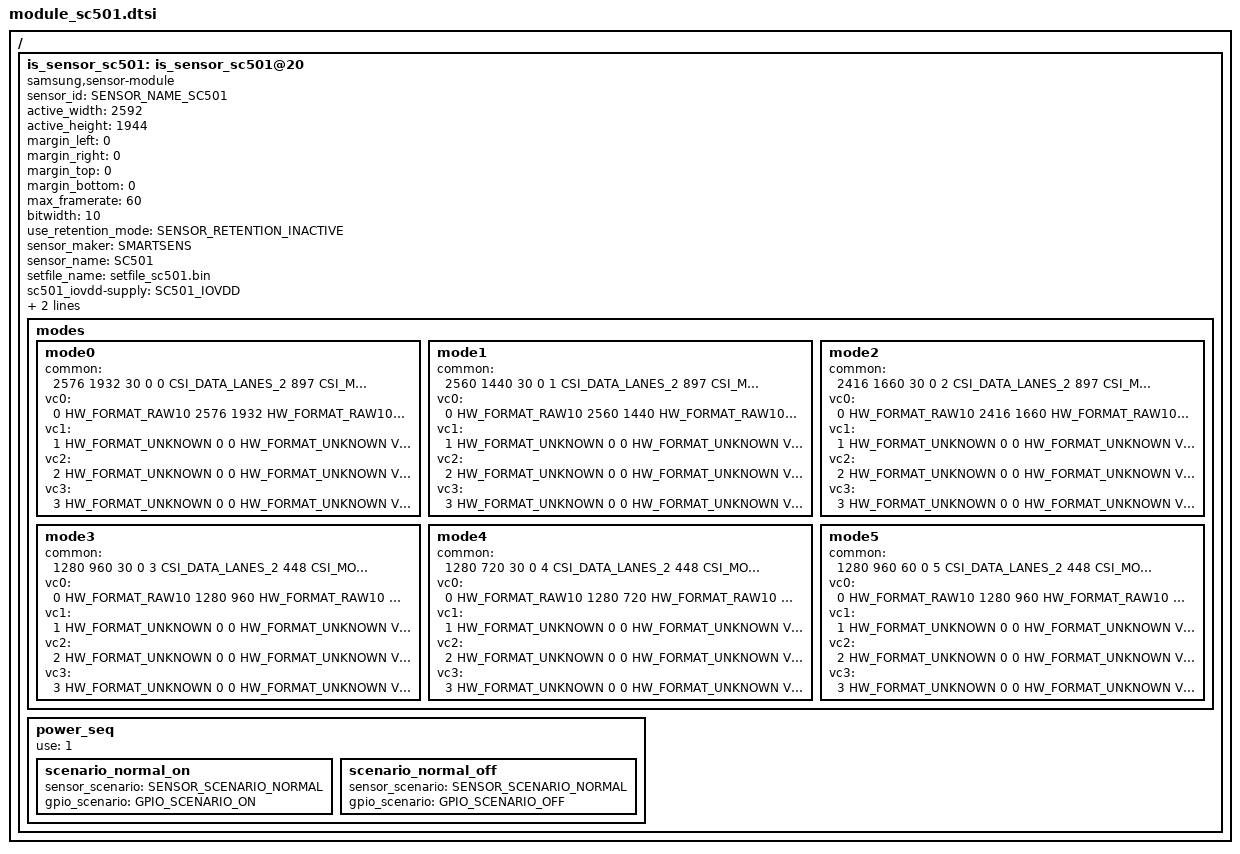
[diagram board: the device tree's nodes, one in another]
/*
 * SAMSUNG EXYNOSxxxx board camera device tree source
 *
 * Copyright (c) 2022 Samsung Electronics Co., Ltd.
 *        http://www.samsung.com
 *
 * This program is free software; you can redistribute it and/or modify
 * it under the terms of the GNU General Public License version 2 as
 * published by the Free Software Foundation.
 */

#include <dt-bindings/camera/exynos_is_dt.h>

#ifndef USE_VENDOR_PWR_PIN_NAME
#define SC501_IOVDD	<>
#define SC501_AVDD	<>
#define SC501_DVDD	<>
#endif

/ {
	fragment@camera {
		target-path = "/";
		__overlay__ {
			is_sensor_sc501: is_sensor_sc501@20 {
				compatible = "samsung,sensor-module";

				/* common */
				sensor_id = <SENSOR_NAME_SC501>;
				active_width = <2592>;
				active_height = <1944>;
				margin_left = <0>;
				margin_right = <0>;
				margin_top = <0>;
				margin_bottom = <0>;
				max_framerate = <60>;
				bitwidth = <10>;
				use_retention_mode = <SENSOR_RETENTION_INACTIVE>;
				sensor_maker = "SMARTSENS";
				sensor_name = "SC501";
				setfile_name = "setfile_sc501.bin";

				sc501_iovdd-supply = SC501_IOVDD;
				sc501_avdd-supply = SC501_AVDD;
				sc501_dvdd-supply = SC501_DVDD;

				status = "okay";

				/* sensor modes */
				modes {
						/* common = <width, height, fps, settle, mode, lane, speed, interleave, lrte, pd_mode> */
						/* vcX = <map, hwformat, width, height, hwformat, type, width, height> */

					/* 0 : 2576x1932@30fps 4:3 */
					mode0 {
						common = <2576 1932 30 0 0 CSI_DATA_LANES_2 897 CSI_MODE_VC_ONLY LRTE_DISABLE PD_NONE EX_NONE>;
						vc0 = </* in */ 0 HW_FORMAT_RAW10 2576 1932	/* out */ HW_FORMAT_RAW10 VC_NOTHING 0 0>;
						vc1 = </* in */ 1 HW_FORMAT_UNKNOWN 0 0		/* out */ HW_FORMAT_UNKNOWN VC_NOTHING 0 0>;
						vc2 = </* in */ 2 HW_FORMAT_UNKNOWN 0 0		/* out */ HW_FORMAT_UNKNOWN VC_NOTHING 0 0>;
						vc3 = </* in */ 3 HW_FORMAT_UNKNOWN 0 0		/* out */ HW_FORMAT_UNKNOWN VC_NOTHING 0 0>;
					};

					/* 1 : 2560x1440@30fps 16:9 */
					mode1 {
						common = <2560 1440 30 0 1 CSI_DATA_LANES_2 897 CSI_MODE_VC_ONLY LRTE_DISABLE PD_NONE EX_NONE>;
						vc0 = </* in */ 0 HW_FORMAT_RAW10 2560 1440	/* out */ HW_FORMAT_RAW10 VC_NOTHING 0 0>;
						vc1 = </* in */ 1 HW_FORMAT_UNKNOWN 0 0		/* out */ HW_FORMAT_UNKNOWN VC_NOTHING 0 0>;
						vc2 = </* in */ 2 HW_FORMAT_UNKNOWN 0 0		/* out */ HW_FORMAT_UNKNOWN VC_NOTHING 0 0>;
						vc3 = </* in */ 3 HW_FORMAT_UNKNOWN 0 0		/* out */ HW_FORMAT_UNKNOWN VC_NOTHING 0 0>;
					};

					/* 2 : 2416x1660@30fps */
					mode2 {
						common = <2416 1660 30 0 2 CSI_DATA_LANES_2 897 CSI_MODE_VC_ONLY LRTE_DISABLE PD_NONE EX_NONE>;
						vc0 = </* in */ 0 HW_FORMAT_RAW10 2416 1660	/* out */ HW_FORMAT_RAW10 VC_NOTHING 0 0>;
						vc1 = </* in */ 1 HW_FORMAT_UNKNOWN 0 0		/* out */ HW_FORMAT_UNKNOWN VC_NOTHING 0 0>;
						vc2 = </* in */ 2 HW_FORMAT_UNKNOWN 0 0		/* out */ HW_FORMAT_UNKNOWN VC_NOTHING 0 0>;
						vc3 = </* in */ 3 HW_FORMAT_UNKNOWN 0 0		/* out */ HW_FORMAT_UNKNOWN VC_NOTHING 0 0>;
					};

					/* 3 : 1280x960@30fps 4:3 */
					mode3 {
						common = <1280 960 30 0 3 CSI_DATA_LANES_2 448 CSI_MODE_VC_ONLY LRTE_DISABLE PD_NONE EX_NONE>;
						vc0 = </* in */ 0 HW_FORMAT_RAW10 1280 960	/* out */ HW_FORMAT_RAW10 VC_NOTHING 0 0>;
						vc1 = </* in */ 1 HW_FORMAT_UNKNOWN 0 0		/* out */ HW_FORMAT_UNKNOWN VC_NOTHING 0 0>;
						vc2 = </* in */ 2 HW_FORMAT_UNKNOWN 0 0		/* out */ HW_FORMAT_UNKNOWN VC_NOTHING 0 0>;
						vc3 = </* in */ 3 HW_FORMAT_UNKNOWN 0 0		/* out */ HW_FORMAT_UNKNOWN VC_NOTHING 0 0>;
					};

					/* 4 : 1280x720@30fps 16:9 */
					mode4 {
						common = <1280 720 30 0 4 CSI_DATA_LANES_2 448 CSI_MODE_VC_ONLY LRTE_DISABLE PD_NONE EX_NONE>;
						vc0 = </* in */ 0 HW_FORMAT_RAW10 1280 720	/* out */ HW_FORMAT_RAW10 VC_NOTHING 0 0>;
						vc1 = </* in */ 1 HW_FORMAT_UNKNOWN 0 0		/* out */ HW_FORMAT_UNKNOWN VC_NOTHING 0 0>;
						vc2 = </* in */ 2 HW_FORMAT_UNKNOWN 0 0		/* out */ HW_FORMAT_UNKNOWN VC_NOTHING 0 0>;
						vc3 = </* in */ 3 HW_FORMAT_UNKNOWN 0 0		/* out */ HW_FORMAT_UNKNOWN VC_NOTHING 0 0>;
					};

					/* 5 : 1280x960@60fps 4:3 */
					mode5 {
						common = <1280 960 60 0 5 CSI_DATA_LANES_2 448 CSI_MODE_VC_ONLY LRTE_DISABLE PD_NONE EX_NONE>;
						vc0 = </* in */ 0 HW_FORMAT_RAW10 1280 960	/* out */ HW_FORMAT_RAW10 VC_NOTHING 0 0>;
						vc1 = </* in */ 1 HW_FORMAT_UNKNOWN 0 0		/* out */ HW_FORMAT_UNKNOWN VC_NOTHING 0 0>;
						vc2 = </* in */ 2 HW_FORMAT_UNKNOWN 0 0		/* out */ HW_FORMAT_UNKNOWN VC_NOTHING 0 0>;
						vc3 = </* in */ 3 HW_FORMAT_UNKNOWN 0 0		/* out */ HW_FORMAT_UNKNOWN VC_NOTHING 0 0>;
					};

				};

				power_seq {
					use = <1>;

					scenario_normal_on {
						sensor_scenario = <SENSOR_SCENARIO_NORMAL>;
						gpio_scenario = <GPIO_SCENARIO_ON>;

						/* A start node number should be over the 10 for reserved number 0~9. */
						/* pname = "name"; pin = <act value dealy voltage>; gpio = <gpx# # 0x1>; */
					};

					scenario_normal_off {
						sensor_scenario = <SENSOR_SCENARIO_NORMAL>;
						gpio_scenario = <GPIO_SCENARIO_OFF>;

						/* A start node number should be over the 10 for reserved number 0~9. */
						/* pname = "name"; pin = <act value dealy voltage>; gpio = <gpx# # 0x1>; */
					};
#if 0
					scenario_read_rom_on {
						sensor_scenario = <SENSOR_SCENARIO_READ_ROM>;
						gpio_scenario = <GPIO_SCENARIO_ON>;
					};

					scenario_read_rom_off {
						sensor_scenario = <SENSOR_SCENARIO_READ_ROM>;
						gpio_scenario = <GPIO_SCENARIO_OFF>;
					};

					scenario_vision_on {
						sensor_scenario = <SENSOR_SCENARIO_VISION>;
						gpio_scenario = <GPIO_SCENARIO_ON>;

						/* A start node number should be over the 10 for reserved number 0~9. */
						/* pname = "name"; 		pin = <act value dealy voltage>;	gpio = <gpx# # 0x1>; */
					};

					scenario_vision_off {
						sensor_scenario = <SENSOR_SCENARIO_VISION>;
						gpio_scenario = <GPIO_SCENARIO_OFF>;

						/* A start node number should be over the 10 for reserved number 0~9. */
						/* pname = "name"; 		pin = <act value dealy voltage>;	gpio = <gpx# # 0x1>; */
					};
#endif
				};
			}; /*is_sensor_sc501 */

		}; /* end of __overlay__ */
	}; /* end of fragment */
}; /* end of root */
